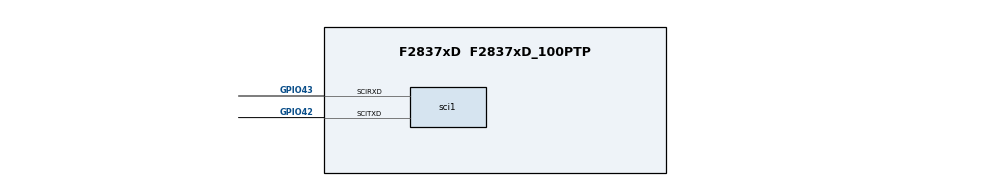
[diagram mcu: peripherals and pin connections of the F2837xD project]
/**
 *
 * @cliArgs --device "F2837xD" --part "F2837xD_100PTP" --package "F2837xD_100PTP" --context "CPU1" --product "C2000WARE@26.01.00.00"
 * @versions {"tool":"1.28.1+4785"}
 */

/**
 * Import the modules used in this configuration.
 */
const cputimer  = scripting.addModule("/driverlib/cputimer.js", {}, false);
const cputimer1 = cputimer.addInstance();
const gpio      = scripting.addModule("/driverlib/gpio.js", {}, false);
const gpio1     = gpio.addInstance();
const sci       = scripting.addModule("/driverlib/sci.js", {}, false);
const sci1      = sci.addInstance();

/**
 * Write custom configuration values to the imported modules.
 */
const divider4       = system.clockTree["LOSPCP"];
divider4.divideValue = 1;

cputimer1.$name           = "CPUTIMER0_sci";
cputimer1.timerPeriod     = 10000;
cputimer1.enableInterrupt = true;

gpio1.$name     = "led";
gpio1.direction = "GPIO_DIR_MODE_OUT";

sci1.$name                 = "sci";
sci1.baudRates             = 12000000;
sci1.sci.scirxdPin.$assign = "GPIO43";
sci1.sci.scitxdPin.$assign = "GPIO42";
sci1.rxQual.$name          = "myGPIOQUAL0";
sci1.txQual.$name          = "myGPIOQUAL1";

/**
 * Pinmux solution for unlocked pins/peripherals. This ensures that minor changes to the automatic solver in a future
 * version of the tool will not impact the pinmux you originally saw.  These lines can be completely deleted in order to
 * re-solve from scratch.
 */
gpio1.gpioPin.$suggestSolution = "GPIO11";
sci1.sci.$suggestSolution      = "SCIA";
